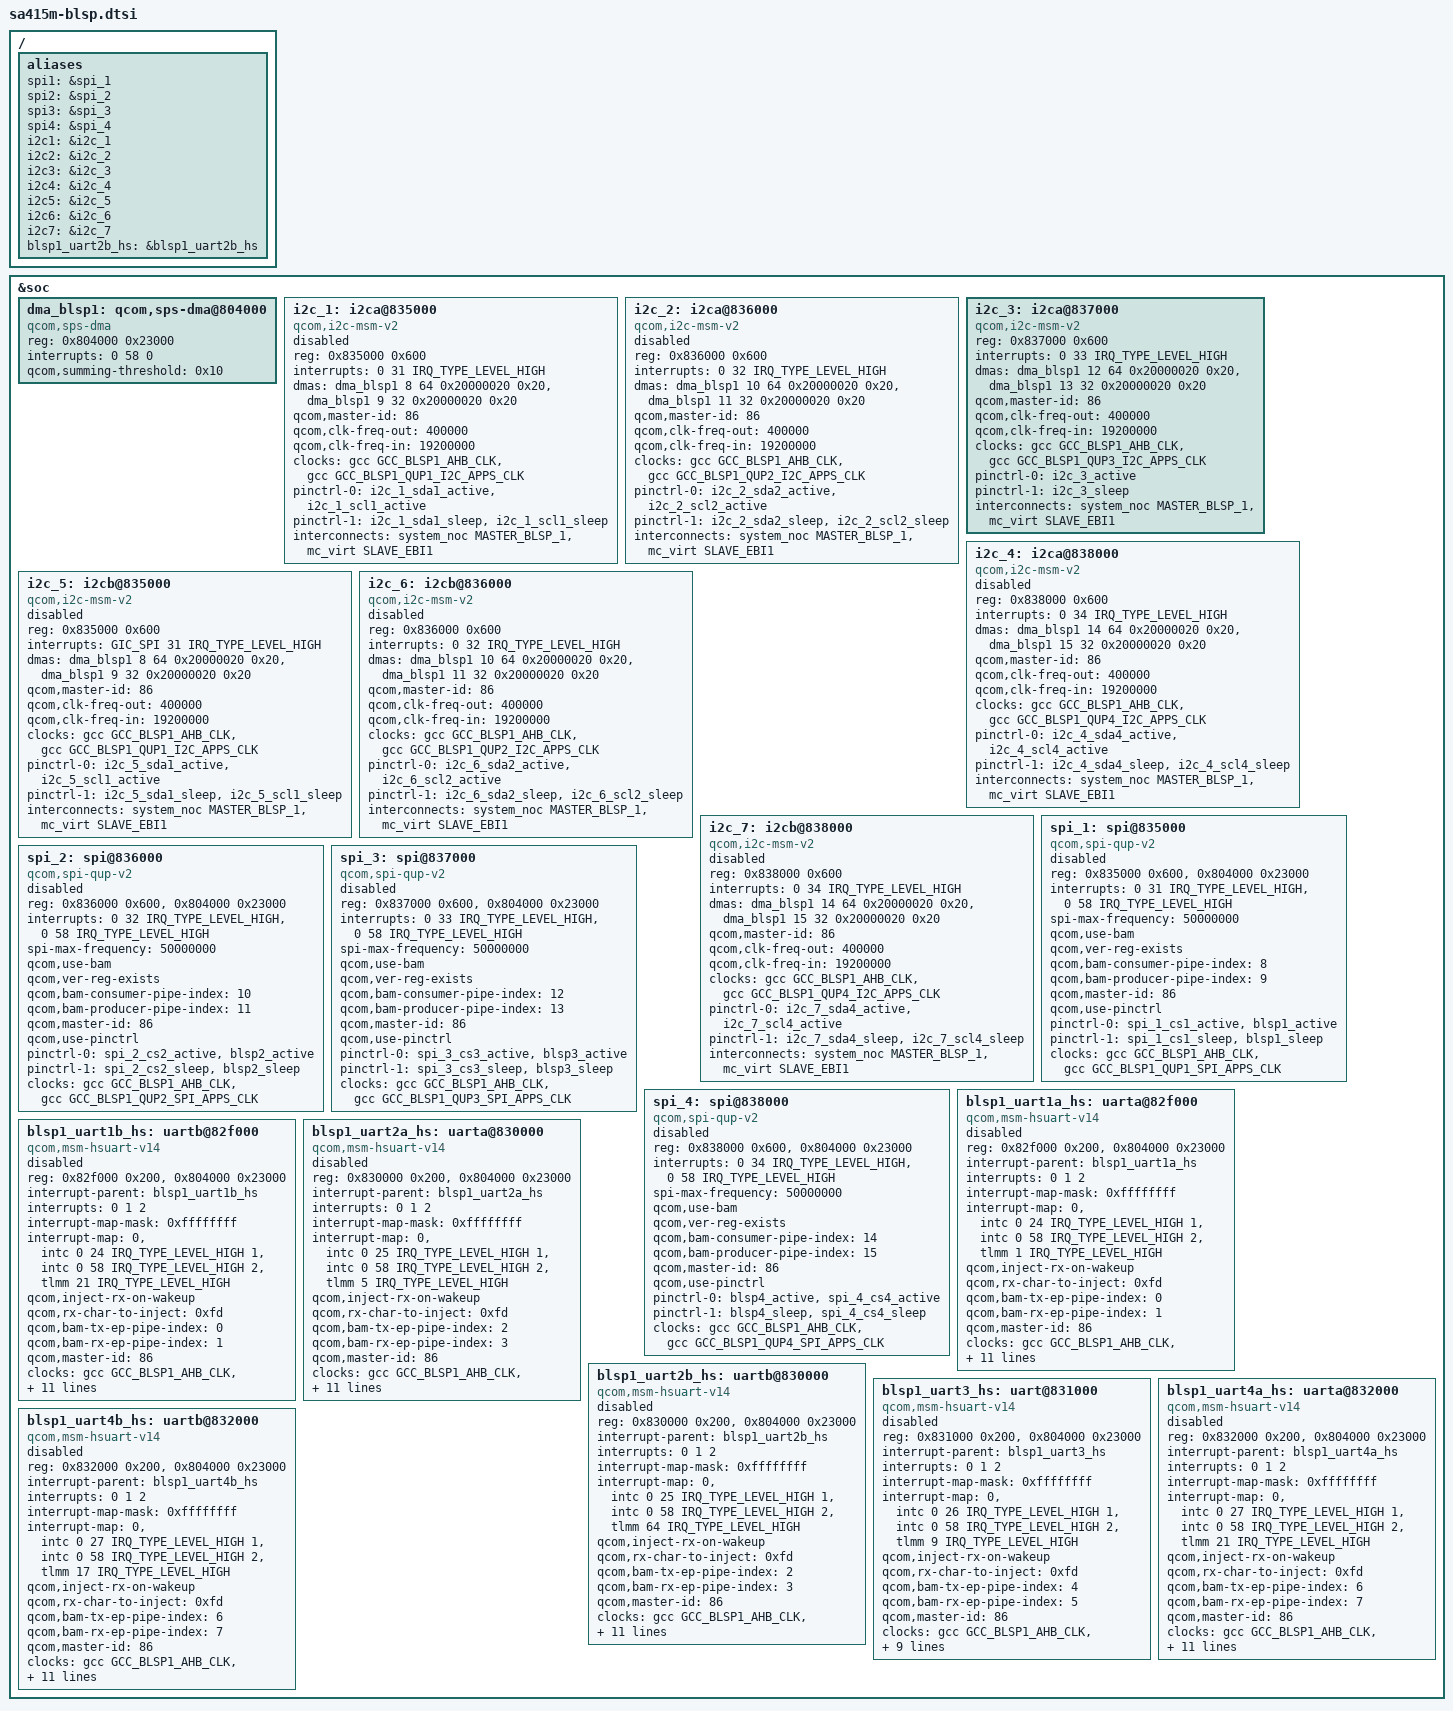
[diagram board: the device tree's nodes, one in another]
/ {
	aliases {
		spi1 = &spi_1;
		spi2 = &spi_2;
		spi3 = &spi_3;
		spi4 = &spi_4;
		i2c1 = &i2c_1;
		i2c2 = &i2c_2;
		i2c3 = &i2c_3;
		i2c4 = &i2c_4;
		i2c5 = &i2c_5;
		i2c6 = &i2c_6;
		i2c7 = &i2c_7;
		blsp1_uart2b_hs = &blsp1_uart2b_hs;
	};
};

&soc {
	dma_blsp1: qcom,sps-dma@804000 { /* BLSP1 */
		#dma-cells = <4>;
		compatible = "qcom,sps-dma";
		reg = <0x804000 0x23000>;
		interrupts = <0 58 0>;
		qcom,summing-threshold = <0x10>;
	};

	i2c_1: i2ca@835000 { /* BLSP1 QUP1: GPIO: 2,3*/
		compatible = "qcom,i2c-msm-v2";
		#address-cells = <1>;
		#size-cells = <0>;
		reg = <0x835000 0x600>;
		reg-names = "qup_phys_addr";
		interrupt-names = "qup_irq";
		interrupts = <0 31 IRQ_TYPE_LEVEL_HIGH>;
		dmas = <&dma_blsp1 8 64 0x20000020 0x20>,
				<&dma_blsp1 9 32 0x20000020 0x20>;
		dma-names = "tx", "rx";
		qcom,master-id = <86>;
		qcom,clk-freq-out = <400000>;
		qcom,clk-freq-in  = <19200000>;
		clock-names = "iface_clk", "core_clk";
		clocks = <&gcc GCC_BLSP1_AHB_CLK>,
				<&gcc GCC_BLSP1_QUP1_I2C_APPS_CLK>;
		pinctrl-names = "i2c_active", "i2c_sleep";
		pinctrl-0 = <&i2c_1_sda1_active>, <&i2c_1_scl1_active>;
		pinctrl-1 = <&i2c_1_sda1_sleep>, <&i2c_1_scl1_sleep>;
		interconnect-names = "blsp-ddr";
		interconnects = <&system_noc MASTER_BLSP_1 &mc_virt SLAVE_EBI1>;
		status = "disabled";
	};

	i2c_2: i2ca@836000 { /* BLSP1 QUP2: GPIO: 6,7 */
		compatible = "qcom,i2c-msm-v2";
		#address-cells = <1>;
		#size-cells = <0>;
		reg = <0x836000 0x600>;
		reg-names = "qup_phys_addr";
		interrupt-names = "qup_irq";
		interrupts = <0 32 IRQ_TYPE_LEVEL_HIGH>;
		dmas = <&dma_blsp1 10 64 0x20000020 0x20>,
				<&dma_blsp1 11 32 0x20000020 0x20>;
		dma-names = "tx", "rx";
		qcom,master-id = <86>;
		qcom,clk-freq-out = <400000>;
		qcom,clk-freq-in  = <19200000>;
		clock-names = "iface_clk", "core_clk";
		clocks = <&gcc GCC_BLSP1_AHB_CLK>,
				<&gcc GCC_BLSP1_QUP2_I2C_APPS_CLK>;
		pinctrl-names = "i2c_active", "i2c_sleep";
		pinctrl-0 = <&i2c_2_sda2_active>, <&i2c_2_scl2_active>;
		pinctrl-1 = <&i2c_2_sda2_sleep>, <&i2c_2_scl2_sleep>;
		interconnect-names = "blsp-ddr";
		interconnects = <&system_noc MASTER_BLSP_1 &mc_virt SLAVE_EBI1>;
		status = "disabled";
	};

	i2c_3: i2ca@837000 { /* BLSP1 QUP3: GPIO: 10,11 */
		compatible = "qcom,i2c-msm-v2";
		#address-cells = <1>;
		#size-cells = <0>;
		reg = <0x837000 0x600>;
		reg-names = "qup_phys_addr";
		interrupt-names = "qup_irq";
		interrupts = <0 33 IRQ_TYPE_LEVEL_HIGH>;
		dmas = <&dma_blsp1 12 64 0x20000020 0x20>,
				<&dma_blsp1 13 32 0x20000020 0x20>;
		dma-names = "tx", "rx";
		qcom,master-id = <86>;
		qcom,clk-freq-out = <400000>;
		qcom,clk-freq-in  = <19200000>;
		clock-names = "iface_clk", "core_clk";
		clocks = <&gcc GCC_BLSP1_AHB_CLK>,
				<&gcc GCC_BLSP1_QUP3_I2C_APPS_CLK>;
		pinctrl-names = "i2c_active", "i2c_sleep";
		pinctrl-0 = <&i2c_3_active>;
		pinctrl-1 = <&i2c_3_sleep>;
		interconnect-names = "blsp-ddr";
		interconnects = <&system_noc MASTER_BLSP_1 &mc_virt SLAVE_EBI1>;
		status = "ok";
	};

	i2c_4: i2ca@838000 { /* BLSP1 QUP4: GPIO: 76,77 */
		compatible = "qcom,i2c-msm-v2";
		#address-cells = <1>;
		#size-cells = <0>;
		reg = <0x838000 0x600>;
		reg-names = "qup_phys_addr";
		interrupt-names = "qup_irq";
		interrupts = <0 34 IRQ_TYPE_LEVEL_HIGH>;
		dmas = <&dma_blsp1 14 64 0x20000020 0x20>,
				<&dma_blsp1 15 32 0x20000020 0x20>;
		dma-names = "tx", "rx";
		qcom,master-id = <86>;
		qcom,clk-freq-out = <400000>;
		qcom,clk-freq-in  = <19200000>;
		clock-names = "iface_clk", "core_clk";
		clocks = <&gcc GCC_BLSP1_AHB_CLK>,
				<&gcc GCC_BLSP1_QUP4_I2C_APPS_CLK>;
		pinctrl-names = "i2c_active", "i2c_sleep";
		pinctrl-0 = <&i2c_4_sda4_active>, <&i2c_4_scl4_active>;
		pinctrl-1 = <&i2c_4_sda4_sleep>, <&i2c_4_scl4_sleep>;
		interconnect-names = "blsp-ddr";
		interconnects = <&system_noc MASTER_BLSP_1 &mc_virt SLAVE_EBI1>;
		status = "disabled";
	};

	i2c_5: i2cb@835000 { /* BLSP1 QUP1: GPIO: 74,75 */
		compatible = "qcom,i2c-msm-v2";
		#address-cells = <1>;
		#size-cells = <0>;
		reg = <0x835000 0x600>;
		reg-names = "qup_phys_addr";
		interrupt-names = "qup_irq";
		interrupts = <GIC_SPI 31 IRQ_TYPE_LEVEL_HIGH>;
		dmas = <&dma_blsp1 8 64 0x20000020 0x20>,
				<&dma_blsp1 9 32 0x20000020 0x20>;
		dma-names = "tx", "rx";
		qcom,master-id = <86>;
		qcom,clk-freq-out = <400000>;
		qcom,clk-freq-in  = <19200000>;
		clock-names = "iface_clk", "core_clk";
		clocks = <&gcc GCC_BLSP1_AHB_CLK>,
				<&gcc GCC_BLSP1_QUP1_I2C_APPS_CLK>;
		pinctrl-names = "i2c_active", "i2c_sleep";
		pinctrl-0 = <&i2c_5_sda1_active>, <&i2c_5_scl1_active>;
		pinctrl-1 = <&i2c_5_sda1_sleep>, <&i2c_5_scl1_sleep>;
		interconnect-names = "blsp-ddr";
		interconnects = <&system_noc MASTER_BLSP_1 &mc_virt SLAVE_EBI1>;
		status = "disabled";
	};

	i2c_6: i2cb@836000 { /* BLSP1 QUP2: GPIO: 65,66 */
		compatible = "qcom,i2c-msm-v2";
		#address-cells = <1>;
		#size-cells = <0>;
		reg = <0x836000 0x600>;
		reg-names = "qup_phys_addr";
		interrupt-names = "qup_irq";
		interrupts = <0 32 IRQ_TYPE_LEVEL_HIGH>;
		dmas = <&dma_blsp1 10 64 0x20000020 0x20>,
				<&dma_blsp1 11 32 0x20000020 0x20>;
		dma-names = "tx", "rx";
		qcom,master-id = <86>;
		qcom,clk-freq-out = <400000>;
		qcom,clk-freq-in  = <19200000>;
		clock-names = "iface_clk", "core_clk";
		clocks = <&gcc GCC_BLSP1_AHB_CLK>,
				<&gcc GCC_BLSP1_QUP2_I2C_APPS_CLK>;
		pinctrl-names = "i2c_active", "i2c_sleep";
		pinctrl-0 = <&i2c_6_sda2_active>, <&i2c_6_scl2_active>;
		pinctrl-1 = <&i2c_6_sda2_sleep>, <&i2c_6_scl2_sleep>;
		interconnect-names = "blsp-ddr";
		interconnects = <&system_noc MASTER_BLSP_1 &mc_virt SLAVE_EBI1>;
		status = "disabled";
	};

	i2c_7: i2cb@838000 { /* BLSP1 QUP4: GPIO: 18,19 */
		compatible = "qcom,i2c-msm-v2";
		#address-cells = <1>;
		#size-cells = <0>;
		reg = <0x838000 0x600>;
		reg-names = "qup_phys_addr";
		interrupt-names = "qup_irq";
		interrupts = <0 34 IRQ_TYPE_LEVEL_HIGH>;
		dmas = <&dma_blsp1 14 64 0x20000020 0x20>,
			<&dma_blsp1 15 32 0x20000020 0x20>;
		dma-names = "tx", "rx";
		qcom,master-id = <86>;
		qcom,clk-freq-out = <400000>;
		qcom,clk-freq-in  = <19200000>;
		clock-names = "iface_clk", "core_clk";
		clocks = <&gcc GCC_BLSP1_AHB_CLK>,
				<&gcc GCC_BLSP1_QUP4_I2C_APPS_CLK>;
		pinctrl-names = "i2c_active", "i2c_sleep";
		pinctrl-0 = <&i2c_7_sda4_active>, <&i2c_7_scl4_active>;
		pinctrl-1 = <&i2c_7_sda4_sleep>, <&i2c_7_scl4_sleep>;
		interconnect-names = "blsp-ddr";
		interconnects = <&system_noc MASTER_BLSP_1 &mc_virt SLAVE_EBI1>;
		status = "disabled";
	};

	spi_1: spi@835000 { /* BLSP1 QUP1: GPIO: 72,73,74,75 */
		compatible = "qcom,spi-qup-v2";
		#address-cells = <1>;
		#size-cells = <0>;
		reg-names = "spi_physical", "spi_bam_physical";
		reg = <0x835000 0x600>,
			<0x804000 0x23000>;
		interrupt-names = "spi_irq", "spi_bam_irq";
		interrupts = <0 31 IRQ_TYPE_LEVEL_HIGH>,
					<0 58 IRQ_TYPE_LEVEL_HIGH>;
		spi-max-frequency = <50000000>;
		qcom,use-bam;
		qcom,ver-reg-exists;
		qcom,bam-consumer-pipe-index = <8>;
		qcom,bam-producer-pipe-index = <9>;
		qcom,master-id = <86>;
		qcom,use-pinctrl;
		pinctrl-names = "spi_default", "spi_sleep";
		pinctrl-0 = <&spi_1_cs1_active>, <&blsp1_active>;
		pinctrl-1 = <&spi_1_cs1_sleep>, <&blsp1_sleep>;
		clock-names = "iface_clk", "core_clk";
		clocks = <&gcc GCC_BLSP1_AHB_CLK>,
				<&gcc GCC_BLSP1_QUP1_SPI_APPS_CLK>;
		status = "disabled";
	};

	spi_2: spi@836000 { /* BLSP1 QUP2: GPIO: 4,5,6,7 */
		compatible = "qcom,spi-qup-v2";
		#address-cells = <1>;
		#size-cells = <0>;
		reg-names = "spi_physical", "spi_bam_physical";
		reg = <0x836000 0x600>,
			<0x804000 0x23000>;
		interrupt-names = "spi_irq", "spi_bam_irq";
		interrupts = <0 32 IRQ_TYPE_LEVEL_HIGH>,
					<0 58 IRQ_TYPE_LEVEL_HIGH>;
		spi-max-frequency = <50000000>;
		qcom,use-bam;
		qcom,ver-reg-exists;
		qcom,bam-consumer-pipe-index = <10>;
		qcom,bam-producer-pipe-index = <11>;
		qcom,master-id = <86>;
		qcom,use-pinctrl;
		pinctrl-names = "spi_default", "spi_sleep";
		pinctrl-0 = <&spi_2_cs2_active>, <&blsp2_active>;
		pinctrl-1 = <&spi_2_cs2_sleep>, <&blsp2_sleep>;
		clock-names = "iface_clk", "core_clk";
		clocks = <&gcc GCC_BLSP1_AHB_CLK>,
				<&gcc GCC_BLSP1_QUP2_SPI_APPS_CLK>;
		status = "disabled";
	};

	spi_3: spi@837000 { /* BLSP1 QUP3: GPIO: 8,9,10,11 */
		compatible = "qcom,spi-qup-v2";
		#address-cells = <1>;
		#size-cells = <0>;
		reg-names = "spi_physical", "spi_bam_physical";
		reg = <0x837000 0x600>,
			<0x804000 0x23000>;
		interrupt-names = "spi_irq", "spi_bam_irq";
		interrupts = <0 33 IRQ_TYPE_LEVEL_HIGH>,
					<0 58 IRQ_TYPE_LEVEL_HIGH>;
		spi-max-frequency = <50000000>;
		qcom,use-bam;
		qcom,ver-reg-exists;
		qcom,bam-consumer-pipe-index = <12>;
		qcom,bam-producer-pipe-index = <13>;
		qcom,master-id = <86>;
		qcom,use-pinctrl;
		pinctrl-names = "spi_default", "spi_sleep";
		pinctrl-0 = <&spi_3_cs3_active>, <&blsp3_active>;
		pinctrl-1 = <&spi_3_cs3_sleep>, <&blsp3_sleep>;
		clock-names = "iface_clk", "core_clk";
		clocks = <&gcc GCC_BLSP1_AHB_CLK>,
				<&gcc GCC_BLSP1_QUP3_SPI_APPS_CLK>;
		status = "disabled";
	};

	spi_4: spi@838000 { /* BLSP1 QUP4: GPIO: 16,17,18,19 */
		compatible = "qcom,spi-qup-v2";
		#address-cells = <1>;
		#size-cells = <0>;
		reg-names = "spi_physical", "spi_bam_physical";
		reg = <0x838000 0x600>,
			<0x804000 0x23000>;
		interrupt-names = "spi_irq", "spi_bam_irq";
		interrupts = <0 34 IRQ_TYPE_LEVEL_HIGH>,
					<0 58 IRQ_TYPE_LEVEL_HIGH>;
		spi-max-frequency = <50000000>;
		qcom,use-bam;
		qcom,ver-reg-exists;
		qcom,bam-consumer-pipe-index = <14>;
		qcom,bam-producer-pipe-index = <15>;
		qcom,master-id = <86>;
		qcom,use-pinctrl;
		pinctrl-names = "spi_default", "spi_sleep";
		pinctrl-0 = <&blsp4_active>, <&spi_4_cs4_active>;
		pinctrl-1 = <&blsp4_sleep>, <&spi_4_cs4_sleep>;
		clock-names = "iface_clk", "core_clk";
		clocks = <&gcc GCC_BLSP1_AHB_CLK>,
				<&gcc GCC_BLSP1_QUP4_SPI_APPS_CLK>;
		status = "disabled";
	};

	blsp1_uart1a_hs: uarta@82f000 { /* BLSP1 UART1: GPIO: 0,1,2,3 */
		compatible = "qcom,msm-hsuart-v14";
		reg-names = "core_mem", "bam_mem";
		reg = <0x82f000 0x200>,
			<0x804000 0x23000>;
		interrupt-names = "core_irq", "bam_irq", "wakeup_irq";
		#address-cells = <0>;
		interrupt-parent = <&blsp1_uart1a_hs>;
		interrupts = <0 1 2>;
		#interrupt-cells = <1>;
		interrupt-map-mask = <0xffffffff>;
		interrupt-map = <0 &intc 0 24 IRQ_TYPE_LEVEL_HIGH
						1 &intc 0 58 IRQ_TYPE_LEVEL_HIGH
						2 &tlmm 1 IRQ_TYPE_LEVEL_HIGH>;
		qcom,inject-rx-on-wakeup;
		qcom,rx-char-to-inject = <0xfd>;
		qcom,bam-tx-ep-pipe-index = <0>;
		qcom,bam-rx-ep-pipe-index = <1>;
		qcom,master-id = <86>;
		clock-names = "iface_clk", "core_clk";
		clocks = <&gcc GCC_BLSP1_AHB_CLK>,
				<&gcc GCC_BLSP1_UART1_APPS_CLK>;
		pinctrl-names = "sleep", "default";
		pinctrl-0 = <&blsp1_uart1a_tx1_sleep>,
		<&blsp1_uart1a_rx1_sleep>, <&blsp1_uart1a_cts1_sleep>,
		<&blsp1_uart1a_rfr1_sleep>;
		pinctrl-1 = <&blsp1_uart1a_tx1_active>,
		<&blsp1_uart1a_rx1_active>, <&blsp1_uart1a_cts1_active>,
		<&blsp1_uart1a_rfr1_active>;
		interconnect-names ="blsp-ddr";
		interconnects = <&system_noc MASTER_BLSP_1 &mc_virt SLAVE_EBI1>;
		status = "disabled";
	};

	blsp1_uart1b_hs: uartb@82f000 { /* BLSP1 UART1: GPIO: 20,21,22,23 */
		compatible = "qcom,msm-hsuart-v14";
		reg-names = "core_mem", "bam_mem";
		reg = <0x82f000 0x200>,
			<0x804000 0x23000>;
		interrupt-names = "core_irq", "bam_irq", "wakeup_irq";
		#address-cells = <0>;
		interrupt-parent = <&blsp1_uart1b_hs>;
		interrupts = <0 1 2>;
		#interrupt-cells = <1>;
		interrupt-map-mask = <0xffffffff>;
		interrupt-map = <0 &intc 0 24 IRQ_TYPE_LEVEL_HIGH
						1 &intc 0 58 IRQ_TYPE_LEVEL_HIGH
						2 &tlmm 21 IRQ_TYPE_LEVEL_HIGH>;
		qcom,inject-rx-on-wakeup;
		qcom,rx-char-to-inject = <0xfd>;
		qcom,bam-tx-ep-pipe-index = <0>;
		qcom,bam-rx-ep-pipe-index = <1>;
		qcom,master-id = <86>;
		clock-names = "iface_clk", "core_clk";
		clocks = <&gcc GCC_BLSP1_AHB_CLK>,
				<&gcc GCC_BLSP1_UART1_APPS_CLK>;
		pinctrl-names = "sleep", "default";
		pinctrl-0 = <&blsp1_uart1b_tx1_sleep>,
		<&blsp1_uart1b_rx1_sleep>, <&blsp1_uart1b_cts1_sleep>, <&blsp1_uart1b_rfr1_sleep>;
		pinctrl-1 = <&blsp1_uart1b_tx1_active>,
		<&blsp1_uart1b_rx1_active>, <&blsp1_uart1b_cts1_active>, <&blsp1_uart1b_rfr1_active>;
		interconnect-names ="blsp-ddr";
		interconnects = <&system_noc MASTER_BLSP_1 &mc_virt SLAVE_EBI1>;
		status = "disabled";
	};

	blsp1_uart2a_hs: uarta@830000 { /* BLSP1 UART2: GPIO: 4,5,6,7 */
		compatible = "qcom,msm-hsuart-v14";
		reg-names = "core_mem", "bam_mem";
		reg = <0x830000 0x200>,
			<0x804000 0x23000>;
		interrupt-names = "core_irq", "bam_irq", "wakeup_irq";
		#address-cells = <0>;
		interrupt-parent = <&blsp1_uart2a_hs>;
		interrupts = <0 1 2>;
		#interrupt-cells = <1>;
		interrupt-map-mask = <0xffffffff>;
		interrupt-map = <0 &intc 0 25 IRQ_TYPE_LEVEL_HIGH
						1 &intc 0 58 IRQ_TYPE_LEVEL_HIGH
						2 &tlmm 5 IRQ_TYPE_LEVEL_HIGH>;
		qcom,inject-rx-on-wakeup;
		qcom,rx-char-to-inject = <0xfd>;
		qcom,bam-tx-ep-pipe-index = <2>;
		qcom,bam-rx-ep-pipe-index = <3>;
		qcom,master-id = <86>;
		clock-names = "iface_clk", "core_clk";
		clocks = <&gcc GCC_BLSP1_AHB_CLK>,
				<&gcc GCC_BLSP1_UART2_APPS_CLK>;
		pinctrl-names = "sleep", "default";
		pinctrl-0 = <&blsp1_uart2a_tx2_sleep>,
		<&blsp1_uart2a_rx2_sleep>, <&blsp1_uart2a_cts2_sleep>, <&blsp1_uart2a_rfr2_sleep>;
		pinctrl-1 = <&blsp1_uart2a_tx2_active>,
		<&blsp1_uart2a_rx2_active>, <&blsp1_uart2a_cts2_active>, <&blsp1_uart2a_rfr2_active>;
		interconnect-names ="blsp-ddr";
		interconnects = <&system_noc MASTER_BLSP_1 &mc_virt SLAVE_EBI1>;
		status = "disabled";
	};

	blsp1_uart2b_hs: uartb@830000 { /* BLSP1 UART2: GPIO: 63,64,65,66 */
		compatible = "qcom,msm-hsuart-v14";
		reg-names = "core_mem", "bam_mem";
		reg = <0x830000 0x200>,
			<0x804000 0x23000>;
		interrupt-names = "core_irq", "bam_irq", "wakeup_irq";
		#address-cells = <0>;
		interrupt-parent = <&blsp1_uart2b_hs>;
		interrupts = <0 1 2>;
		#interrupt-cells = <1>;
		interrupt-map-mask = <0xffffffff>;
		interrupt-map = <0 &intc 0 25 IRQ_TYPE_LEVEL_HIGH
						1 &intc 0 58 IRQ_TYPE_LEVEL_HIGH
						2 &tlmm 64 IRQ_TYPE_LEVEL_HIGH>;
		qcom,inject-rx-on-wakeup;
		qcom,rx-char-to-inject = <0xfd>;
		qcom,bam-tx-ep-pipe-index = <2>;
		qcom,bam-rx-ep-pipe-index = <3>;
		qcom,master-id = <86>;
		clock-names = "iface_clk", "core_clk";
		clocks = <&gcc GCC_BLSP1_AHB_CLK>,
				<&gcc GCC_BLSP1_UART2_APPS_CLK>;
		pinctrl-names = "sleep", "default";
		pinctrl-0 = <&blsp1_uart2b_tx2_sleep>,
		<&blsp1_uart2b_rx2_sleep>, <&blsp1_uart2b_cts2_sleep>, <&blsp1_uart2b_rfr2_sleep>;
		pinctrl-1 = <&blsp1_uart2b_tx2_active>,
		<&blsp1_uart2b_rx2_active>, <&blsp1_uart2b_cts2_active>, <&blsp1_uart2b_rfr2_active>;
		interconnect-names ="blsp-ddr";
		interconnects = <&system_noc MASTER_BLSP_1 &mc_virt SLAVE_EBI1>;
		status = "disabled";
	};

	blsp1_uart3_hs: uart@831000 { /* BLSP1 UART3: GPIO: 8,9,10,11 */
		compatible = "qcom,msm-hsuart-v14";
		reg-names = "core_mem", "bam_mem";
		reg = <0x831000 0x200>,
			<0x804000 0x23000>;
		interrupt-names = "core_irq", "bam_irq", "wakeup_irq";
		#address-cells = <0>;
		interrupt-parent = <&blsp1_uart3_hs>;
		interrupts = <0 1 2>;
		#interrupt-cells = <1>;
		interrupt-map-mask = <0xffffffff>;
		interrupt-map = <0 &intc 0 26 IRQ_TYPE_LEVEL_HIGH
						1 &intc 0 58 IRQ_TYPE_LEVEL_HIGH
						2 &tlmm 9 IRQ_TYPE_LEVEL_HIGH>;
		qcom,inject-rx-on-wakeup;
		qcom,rx-char-to-inject = <0xfd>;
		qcom,bam-tx-ep-pipe-index = <4>;
		qcom,bam-rx-ep-pipe-index = <5>;
		qcom,master-id = <86>;
		clock-names = "iface_clk", "core_clk";
		clocks = <&gcc GCC_BLSP1_AHB_CLK>,
				<&gcc GCC_BLSP1_UART3_APPS_CLK>;
		pinctrl-names = "sleep", "default";
		pinctrl-0 = <&blsp1_uart3_tx_sleep>,
		<&blsp1_uart3_rxcts_sleep>, <&blsp1_uart3_rfr_sleep>;
		pinctrl-1 = <&blsp1_uart3_tx_active>,
		<&blsp1_uart3_rxcts_active>, <&blsp1_uart3_rfr_active>;
		interconnect-names ="blsp-ddr";
		interconnects = <&system_noc MASTER_BLSP_1 &mc_virt SLAVE_EBI1>;
		status = "disabled";
	};

	blsp1_uart4a_hs: uarta@832000 { /* BLSP1 UART4: GPIO: 20,21,22,23 */
		compatible = "qcom,msm-hsuart-v14";
		reg-names = "core_mem", "bam_mem";
		reg = <0x832000 0x200>,
			<0x804000 0x23000>;
		interrupt-names = "core_irq", "bam_irq", "wakeup_irq";
		#address-cells = <0>;
		interrupt-parent = <&blsp1_uart4a_hs>;
		interrupts = <0 1 2>;
		#interrupt-cells = <1>;
		interrupt-map-mask = <0xffffffff>;
		interrupt-map = <0 &intc 0 27 IRQ_TYPE_LEVEL_HIGH
						1 &intc 0 58 IRQ_TYPE_LEVEL_HIGH
						2 &tlmm 21 IRQ_TYPE_LEVEL_HIGH>;
		qcom,inject-rx-on-wakeup;
		qcom,rx-char-to-inject = <0xfd>;
		qcom,bam-tx-ep-pipe-index = <6>;
		qcom,bam-rx-ep-pipe-index = <7>;
		qcom,master-id = <86>;
		clock-names = "iface_clk", "core_clk";
		clocks = <&gcc GCC_BLSP1_AHB_CLK>,
				<&gcc GCC_BLSP1_UART4_APPS_CLK>;
		pinctrl-names = "sleep", "default";
		pinctrl-0 = <&blsp1_uart4a_tx4_sleep>,
		<&blsp1_uart4a_rx4_sleep>, <&blsp1_uart4a_cts4_sleep>, <&blsp1_uart4a_rfr4_sleep>;
		pinctrl-1 = <&blsp1_uart4a_tx4_active>,
		<&blsp1_uart4a_rx4_active>, <&blsp1_uart4a_cts4_active>, <&blsp1_uart4a_rfr4_active>;
		interconnect-names ="blsp-ddr";
		interconnects = <&system_noc MASTER_BLSP_1 &mc_virt SLAVE_EBI1>;
		status = "disabled";
	};

	blsp1_uart4b_hs: uartb@832000 { /* BLSP1 UART4: GPIO: 16,17,18,19 */
		compatible = "qcom,msm-hsuart-v14";
		reg-names = "core_mem", "bam_mem";
		reg = <0x832000 0x200>,
			<0x804000 0x23000>;
		interrupt-names = "core_irq", "bam_irq", "wakeup_irq";
		#address-cells = <0>;
		interrupt-parent = <&blsp1_uart4b_hs>;
		interrupts = <0 1 2>;
		#interrupt-cells = <1>;
		interrupt-map-mask = <0xffffffff>;
		interrupt-map = <0 &intc 0 27 IRQ_TYPE_LEVEL_HIGH
						1 &intc 0 58 IRQ_TYPE_LEVEL_HIGH
						2 &tlmm 17 IRQ_TYPE_LEVEL_HIGH>;
		qcom,inject-rx-on-wakeup;
		qcom,rx-char-to-inject = <0xfd>;
		qcom,bam-tx-ep-pipe-index = <6>;
		qcom,bam-rx-ep-pipe-index = <7>;
		qcom,master-id = <86>;
		clock-names = "iface_clk", "core_clk";
		clocks = <&gcc GCC_BLSP1_AHB_CLK>,
				<&gcc GCC_BLSP1_UART4_APPS_CLK>;
		pinctrl-names = "sleep", "default";
		pinctrl-0 = <&blsp1_uart4b_tx4_sleep>,
		<&blsp1_uart4b_rx4_sleep>, <&blsp1_uart4b_cts4_sleep>, <&blsp1_uart4b_rfr4_sleep>;
		pinctrl-1 = <&blsp1_uart4b_tx4_active>,
		<&blsp1_uart4b_rx4_active>, <&blsp1_uart4b_cts4_active>, <&blsp1_uart4b_rfr4_active>;
		interconnect-names ="blsp-ddr";
		interconnects = <&system_noc MASTER_BLSP_1 &mc_virt SLAVE_EBI1>;
		status = "disabled";
	};
};
